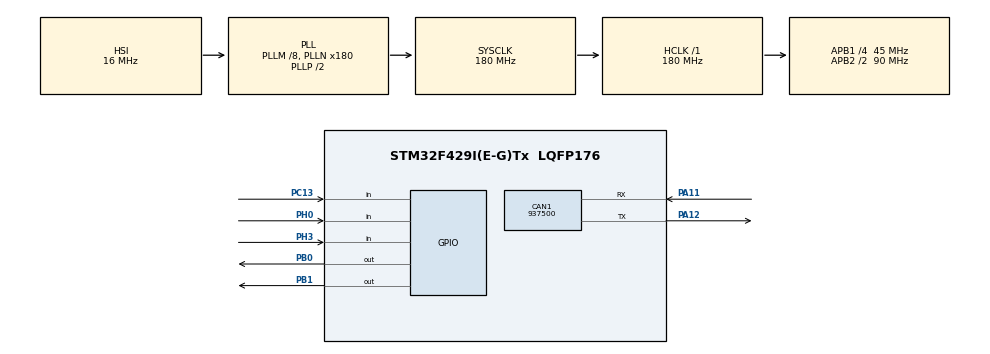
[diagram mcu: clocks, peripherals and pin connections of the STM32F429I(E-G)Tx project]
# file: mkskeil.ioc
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CAN1.CalculateBaudRate=937500
CAN1.CalculateTimeBit=1066
CAN1.CalculateTimeQuantum=355.55555555555554
FREERTOS.Tasks01=defaultTask,0,128,StartDefaultTask,Default,NULL,Dynamic,NULL,NULL
Mcu.Family=STM32F4
Mcu.Name=STM32F429I(E-G)Tx
Mcu.Package=LQFP176
NVIC.PriorityGroup=NVIC_PRIORITYGROUP_4
NVIC.TIM2_IRQn=true\:15\:0\:false\:false\:true\:false\:false\:true\:true
NVIC.TimeBase=TIM2_IRQn
NVIC.TimeBaseIP=TIM2
PA0/WKUP.Mode=SYS_WakeUp0
PA0/WKUP.Signal=SYS_WKUP
PA11.Mode=CAN_Activate
PA11.Signal=CAN1_RX
PA12.Mode=CAN_Activate
PA12.Signal=CAN1_TX
PB0.Signal=GPIO_Output
PB1.Signal=GPIO_Output
PC13.Signal=GPIO_Input
PH0/OSC_IN.Signal=GPIO_Input
PH3.Signal=GPIO_Input
ProjectManager.HeapSize=0x200
ProjectManager.StackSize=0x400
ProjectManager.TargetToolchain=MDK-ARM V5.32
RCC.48MHZClocksFreq_Value=90000000
RCC.AHBFreq_Value=180000000
RCC.APB1CLKDivider=RCC_HCLK_DIV4
RCC.APB1Freq_Value=45000000
RCC.APB1TimFreq_Value=90000000
RCC.APB2CLKDivider=RCC_HCLK_DIV2
RCC.APB2Freq_Value=90000000
RCC.APB2TimFreq_Value=180000000
RCC.CortexFreq_Value=180000000
RCC.HCLKFreq_Value=180000000
RCC.HSE_VALUE=25000000
RCC.HSI_VALUE=16000000
RCC.LSE_VALUE=32768
RCC.PLLM=8
RCC.PLLN=180
RCC.SYSCLKFreq_VALUE=180000000
RCC.SYSCLKSource=RCC_SYSCLKSOURCE_PLLCLK
RCC.VCOOutputFreq_Value=360000000
VP_FREERTOS_VS_CMSIS_V1.Mode=CMSIS_V1
VP_SYS_VS_tim2.Mode=TIM2
board=custom

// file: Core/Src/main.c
/* USER CODE BEGIN Header */
/**
  ******************************************************************************
  * @file           : main.c
  * @brief          : Main program body
  ******************************************************************************
  * @attention
  *
  * Copyright (c) 2026 STMicroelectronics.
  * All rights reserved.
  *
  * This software is licensed under terms that can be found in the LICENSE file
  * in the root directory of this software component.
  * If no LICENSE file comes with this software, it is provided AS-IS.
  *
  ******************************************************************************
  */
/* USER CODE END Header */
#include "main.h"
#include "cmsis_os.h"
#include "mksmot.h"
#include "delay.h"
#include "bsp_can.h"

CAN_HandleTypeDef hcan1;
osThreadId defaultTaskHandle;

uint16_t runSpeed=100;    //电机运行速度
uint8_t runDir  = 1;      //电机运行方向
uint8_t ackStatus = 0;
const int32_t *g_motor_pos_ptr = NULL;   // 全局指针
int32_t g_motor_pos_value = 0;            // 全局值

void SystemClock_Config(void);
static void MX_GPIO_Init(void);
static void MX_CAN1_Init(void);
void StartDefaultTask(void const * argument);

int main(void)
{

  /* MCU Configuration--------------------------------------------------------*/

  /* Reset of all peripherals, Initializes the Flash interface and the Systick. */
  HAL_Init();

  /* Configure the system clock */
  SystemClock_Config();

  /* Initialize all configured peripherals */
  MX_GPIO_Init();
  MX_CAN1_Init();
  /* USER CODE BEGIN 2 */
  // CAN_INIT();
  can_filter_init();
  /* USER CODE END 2 */

  /* Create the thread(s) */
  /* definition and creation of defaultTask */
  osThreadDef(defaultTask, StartDefaultTask, osPriorityNormal, 0, 128);
  defaultTaskHandle = osThreadCreate(osThread(defaultTask), NULL);

  /* Start scheduler */
  osKernelStart();

  /* We should never get here as control is now taken by the scheduler */

  /* Infinite loop */
  while (1)
  {
    const int32_t *pos_ptr = readRealTimeLocation(0x01);
    speedModeRun(1,runDir,runSpeed,2); //从机地址=1，加速度=2
    delay_ms(10);
    ackStatus = waitingForACK();   //等待电机应答d
    delay_ms(3000);     //延时3000ms
  }
}

void SystemClock_Config(void)
{
  RCC_OscInitTypeDef RCC_OscInitStruct = {0};
  RCC_ClkInitTypeDef RCC_ClkInitStruct = {0};

  /** Configure the main internal regulator output voltage
  */
  __HAL_RCC_PWR_CLK_ENABLE();
  __HAL_PWR_VOLTAGESCALING_CONFIG(PWR_REGULATOR_VOLTAGE_SCALE1);

  /** Initializes the RCC Oscillators according to the specified parameters
  * in the RCC_OscInitTypeDef structure.
  */
  RCC_OscInitStruct.OscillatorType = RCC_OSCILLATORTYPE_HSI;
  RCC_OscInitStruct.HSIState = RCC_HSI_ON;
  RCC_OscInitStruct.HSICalibrationValue = RCC_HSICALIBRATION_DEFAULT;
  RCC_OscInitStruct.PLL.PLLState = RCC_PLL_ON;
  RCC_OscInitStruct.PLL.PLLSource = RCC_PLLSOURCE_HSI;
  RCC_OscInitStruct.PLL.PLLM = 8;
  RCC_OscInitStruct.PLL.PLLN = 180;
  RCC_OscInitStruct.PLL.PLLP = RCC_PLLP_DIV2;
  RCC_OscInitStruct.PLL.PLLQ = 4;
  if (HAL_RCC_OscConfig(&RCC_OscInitStruct) != HAL_OK)
  {
    Error_Handler();
  }

  /** Activate the Over-Drive mode
  */
  if (HAL_PWREx_EnableOverDrive() != HAL_OK)
  {
    Error_Handler();
  }

  /** Initializes the CPU, AHB and APB buses clocks
  */
  RCC_ClkInitStruct.ClockType = RCC_CLOCKTYPE_HCLK|RCC_CLOCKTYPE_SYSCLK
                              |RCC_CLOCKTYPE_PCLK1|RCC_CLOCKTYPE_PCLK2;
  RCC_ClkInitStruct.SYSCLKSource = RCC_SYSCLKSOURCE_PLLCLK;
  RCC_ClkInitStruct.AHBCLKDivider = RCC_SYSCLK_DIV1;
  RCC_ClkInitStruct.APB1CLKDivider = RCC_HCLK_DIV4;
  RCC_ClkInitStruct.APB2CLKDivider = RCC_HCLK_DIV2;

  if (HAL_RCC_ClockConfig(&RCC_ClkInitStruct, FLASH_LATENCY_5) != HAL_OK)
  {
    Error_Handler();
  }
}

static void MX_CAN1_Init(void)
{

  hcan1.Instance = CAN1;
  hcan1.Init.Prescaler = 16;
  hcan1.Init.Mode = CAN_MODE_NORMAL;
  hcan1.Init.SyncJumpWidth = CAN_SJW_1TQ;
  hcan1.Init.TimeSeg1 = CAN_BS1_1TQ;
  hcan1.Init.TimeSeg2 = CAN_BS2_1TQ;
  hcan1.Init.TimeTriggeredMode = DISABLE;
  hcan1.Init.AutoBusOff = DISABLE;
  hcan1.Init.AutoWakeUp = DISABLE;
  hcan1.Init.AutoRetransmission = DISABLE;
  hcan1.Init.ReceiveFifoLocked = DISABLE;
  hcan1.Init.TransmitFifoPriority = DISABLE;
  if (HAL_CAN_Init(&hcan1) != HAL_OK)
  {
    Error_Handler();
  }

}

static void MX_GPIO_Init(void)
{
  GPIO_InitTypeDef GPIO_InitStruct = {0};

  /* GPIO Ports Clock Enable */
  __HAL_RCC_GPIOC_CLK_ENABLE();
  __HAL_RCC_GPIOH_CLK_ENABLE();
  __HAL_RCC_GPIOA_CLK_ENABLE();
  __HAL_RCC_GPIOB_CLK_ENABLE();

  /*Configure GPIO pin Output Level */
  HAL_GPIO_WritePin(GPIOB, GPIO_PIN_0|GPIO_PIN_1, GPIO_PIN_RESET);

  /*Configure GPIO pin : PC13 */
  GPIO_InitStruct.Pin = GPIO_PIN_13;
  GPIO_InitStruct.Mode = GPIO_MODE_INPUT;
  GPIO_InitStruct.Pull = GPIO_NOPULL;
  HAL_GPIO_Init(GPIOC, &GPIO_InitStruct);

  /*Configure GPIO pins : PH0 PH3 */
  GPIO_InitStruct.Pin = GPIO_PIN_0|GPIO_PIN_3;
  GPIO_InitStruct.Mode = GPIO_MODE_INPUT;
  GPIO_InitStruct.Pull = GPIO_NOPULL;
  HAL_GPIO_Init(GPIOH, &GPIO_InitStruct);

  /*Configure GPIO pins : PB0 PB1 */
  GPIO_InitStruct.Pin = GPIO_PIN_0|GPIO_PIN_1;
  GPIO_InitStruct.Mode = GPIO_MODE_OUTPUT_PP;
  GPIO_InitStruct.Pull = GPIO_NOPULL;
  GPIO_InitStruct.Speed = GPIO_SPEED_FREQ_LOW;
  HAL_GPIO_Init(GPIOB, &GPIO_InitStruct);

}

void StartDefaultTask(void const * argument)
{
  for(;;)
  {
    osDelay(1);
  }
}

void HAL_TIM_PeriodElapsedCallback(TIM_HandleTypeDef *htim)
{
  if (htim->Instance == TIM2)
  {
    // ticks++;//在某些标准库程序中出现的自定义的但是hal疑似已经有替代了
    HAL_IncTick();
  }
}

void Error_Handler(void)
{
  __disable_irq();
  while (1)
  {
  }
}
